AUTOSAR XML (schema 00049)
package /SwComponent/AdaptiveApplication
  adaptive application sw component type Had
    require port VehicleSpeed: required-interface=VehicleSpeed
  adaptive application sw component type Lad
    require port VehicleSpeed: required-interface=VehicleSpeed
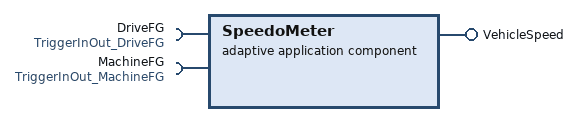
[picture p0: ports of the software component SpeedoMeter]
  adaptive application sw component type SpeedoMeter
    require port DriveFG: required-interface=TriggerInOut_DriveFG
    require port MachineFG: required-interface=TriggerInOut_MachineFG
    provide port VehicleSpeed: provided-interface=VehicleSpeed
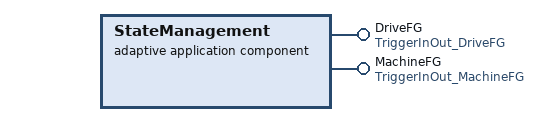
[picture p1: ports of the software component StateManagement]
  adaptive application sw component type StateManagement
    provide port DriveFG: provided-interface=TriggerInOut_DriveFG
    provide port MachineFG: provided-interface=TriggerInOut_MachineFG
package /SwComponent/Composition
  composition sw component type Machine
    4 x component:
      Had: type=Had
      Lad: type=Lad
      SpeedoMeter: type=SpeedoMeter
      StateManagement: type=StateManagement
  composition sw component type System
    component Machine: type=Machine
package /AdaptiveApplication/DltConfig
  6 x dlt log channel to process mapping:
    DltLogChannelToProcessMapping_DltLogChannel_CM_TO_CM: dlt-log-channel=DltLogChannel_CM, process=CM
    DltLogChannelToProcessMapping_DltLogChannel_EM_TO_EM: dlt-log-channel=DltLogChannel_EM, process=EM
    DltLogChannelToProcessMapping_DltLogChannel_Had_TO_Had: dlt-log-channel=DltLogChannel_Had, process=Had
    DltLogChannelToProcessMapping_DltLogChannel_Lad_TO_Lad: dlt-log-channel=DltLogChannel_Lad, process=Lad
    DltLogChannelToProcessMapping_DltLogChannel_Sm_TO_Sm: dlt-log-channel=DltLogChannel_SM, process=SM
    DltLogChannelToProcessMapping_DltLogChannel_SpeedoMeter_TO_SpeedoMeter: dlt-log-channel=DltLogChannel_SpeedoMeter, process=SpeedoMeter
package /AdaptiveApplication/Executable
  6 x executable, all with logging-behavior=USES-LOGGING, version=1.0.0:
    CM: category=PLATFORM_LEVEL, reporting-behavior=REPORTS-EXECUTION-STATE
    EM: category=PLATFORM_LEVEL, reporting-behavior=DOES-NOT-REPORT-EXECUTION-STATE
    Had: category=APPLICATION_LEVEL, reporting-behavior=REPORTS-EXECUTION-STATE
      root sw component prototype Root: application-type=Had
    Lad: category=APPLICATION_LEVEL, reporting-behavior=REPORTS-EXECUTION-STATE
      root sw component prototype Root: application-type=Lad
    SM: category=PLATFORM_LEVEL, reporting-behavior=REPORTS-EXECUTION-STATE
      root sw component prototype Root: application-type=StateManagement
    SpeedoMeter: category=APPLICATION_LEVEL, reporting-behavior=REPORTS-EXECUTION-STATE
      root sw component prototype Root: application-type=SpeedoMeter
package /AdaptiveApplication/Manifest
  7 x service instance to port prototype mapping:
    Had_Root_VehicleSpeed: port-prototype=Root.VehicleSpeed, service-instance=Proxy_VehicleSpeed
    Lad_Root_VehicleSpeed: port-prototype=Root.VehicleSpeed, service-instance=Proxy_VehicleSpeed
    Sm_Root_DriveFG: port-prototype=Root.DriveFG, service-instance=Skeleton_TriggerInOut_DriveFG
    Sm_Root_MachineFG: port-prototype=Root.MachineFG, service-instance=Skeleton_TriggerInOut_MachineFG
    SpeedoMeter_Root_DriveFG: port-prototype=Root.DriveFG, service-instance=Proxy_TriggerInOut_DriveFG
    SpeedoMeter_Root_MachineFG: port-prototype=Root.MachineFG, service-instance=Proxy_TriggerInOut_MachineFG
    SpeedoMeter_Root_VehicleSpeed: port-prototype=Root.VehicleSpeed, service-instance=Skeleton_VehicleSpeed
package /AdaptiveApplication/Process
  6 x process:
    CM: executable=CM, state-dependent-startup-config{function-group-state=[MachineFG.Startup, MachineFG.Restart, MachineFG.Shutdown, MachineFG.Verify], resource-group=NonResourceGroup, startup-config=CM}
      process state machine CM: type=ProcessState
    EM: executable=EM
    Had: executable=Had, state-dependent-startup-config{function-group-state=DriveFG.HighSpd, resource-group=NonResourceGroup, startup-config=Had}
      process state machine Had: type=ProcessState
    Lad: executable=Lad, number-of-restart-attempts=2, state-dependent-startup-config{function-group-state=DriveFG.LowSpd, resource-group=NonResourceGroup, startup-config=Lad}
      process state machine Lad: type=ProcessState
    SM: executable=SM, function-cluster-affiliation=STATE_MANAGEMENT, state-dependent-startup-config{function-group-state=[MachineFG.Startup, MachineFG.Restart, MachineFG.Shutdown, MachineFG.Verify], resource-group=NonResourceGroup, startup-config=SM}
      process state machine SM: type=ProcessState
    SpeedoMeter: executable=SpeedoMeter, state-dependent-startup-config{execution-dependency=SM.Running, function-group-state=MachineFG.Startup, resource-group=NonResourceGroup, startup-config=SpeedoMeter}
      process state machine SpeedoMeter: type=ProcessState
package /AdaptiveApplication/StartupConfig
  startup config set PlatformStartupConfig
    startup config CM: scheduling-policy=SCHED_OTHER, scheduling-priority=0, timeout={enter-timeout-value=1.0, exit-timeout-value=1.0}
  startup config set StartupConfigSet
    4 x startup config, all with scheduling-policy=SCHED_OTHER, scheduling-priority=0, timeout={enter-timeout-value=1.0, exit-timeout-value=1.0}:
      Had
      Lad
      SM
      SpeedoMeter
package /DataType/Implementation/CPP
  14 x std cpp implementation data type:
    DriveState: compu {0x00=kOff, 0x01=kLowSpd, 0x02=kHighSpd, 0x03=kVerify}, type-reference=uint8_t
      namespaces:
        symbol props ara
        symbol props sm
    MachineState: compu {0x00=kOff, 0x01=kStartup, 0x02=kShutdown, 0x03=kRestart, 0x04=kVerify}, type-reference=uint8_t
      namespaces:
        symbol props ara
        symbol props sm
    Speed: type-reference=double
      namespaces:
        symbol props veh
        symbol props sensor
    bool: category=VALUE, type-emitter=FundamentalType
    double: category=VALUE, type-emitter=FundamentalType
    float: category=VALUE, type-emitter=FundamentalType
    int16_t: category=VALUE, header-file=cstdint
    int32_t: category=VALUE, header-file=cstdint
    int64_t: category=VALUE, header-file=cstdint
    int8_t: category=VALUE, header-file=cstdint
    uint16_t: category=VALUE, header-file=cstdint
    uint32_t: category=VALUE, header-file=cstdint
    uint64_t: category=VALUE, header-file=cstdint
    uint8_t: category=VALUE, header-file=cstdint
package /PortInterface/Service
  service interface TriggerInOut_DriveFG
    namespaces:
      symbol props ara
      symbol props sm
      symbol props drivefg
    field Notifier: type=DriveState, has-getter=true, has-notifier=true, has-setter=false
    field Trigger: type=DriveState, has-getter=false, has-notifier=false, has-setter=true
  service interface TriggerInOut_MachineFG
    namespaces:
      symbol props ara
      symbol props sm
      symbol props machinefg
    field Notifier: type=MachineState, has-getter=true, has-notifier=true, has-setter=false
    field Trigger: type=MachineState, has-getter=false, has-notifier=false, has-setter=true
  service interface VehicleSpeed
    namespaces:
      symbol props veh
      symbol props sensor
    events:
      data Speed: type=Speed
package /Platform
  machine Machine: machine-design=Machine, trusted-platform-executable-launch-behavior=NO-TRUSTED-PLATFORM-SUPPORT
    module-instantiations:
      generic module instantiation CmInstantiation: category=COMMUNICATION_MANAGEMENT
      os module instantiation Linux
        resource group NonResourceGroup
        resource group ResourceGroup: cpu-usage=90, mem-usage=1000000000
      log and trace instantiation Log: dlt-ecu-id=Machine
        6 x dlt log channel, all with log-trace-log-modes=CONSOLE:
          DltLogChannel_CM: application-id=CM, context-id=CtxCM, log-trace-default-log-level=FATAL
          DltLogChannel_EM: application-id=EM, context-id=CtxEM, log-trace-default-log-level=FATAL
          DltLogChannel_Had: application-id=Had, context-id=CtxHad, log-trace-default-log-level=INFO
          DltLogChannel_Lad: application-id=Lad, context-id=CtxLad, log-trace-default-log-level=INFO
          DltLogChannel_SM: application-id=SM, context-id=CtxSM, log-trace-default-log-level=INFO
          DltLogChannel_SpeedoMeter: application-id=SpeedoMeter, context-id=CtxSpeedoMeter, log-trace-default-log-level=INFO
    processor CPU
      processor core CORE: core-id=0
package /Platform/FunctionGroup
  function group set FunctionGroupSet
    function-groups:
      mode declaration group prototype DriveFG: type=DriveState
      mode declaration group prototype MachineFG: type=MachineState
package /Platform/ProcessToMachine
  process to machine mapping set ProcessToMachineMappingSet
    6 x process to machine mapping, all with machine=Machine:
      ProcessToMachineMapping_CM_TO_Machine_TO_UnknownModule: process=CM
      ProcessToMachineMapping_EM_TO_Machine_TO_UnknownModule: process=EM
      ProcessToMachineMapping_Had_TO_Machine_TO_UnknownModule: process=Had
      ProcessToMachineMapping_Lad_TO_Machine_TO_UnknownModule: process=Lad
      ProcessToMachineMapping_SM_TO_Machine_TO_UnknownModule: process=SM
      ProcessToMachineMapping_SpeedoMeter_TO_Machine_TO_UnknownModule: process=SpeedoMeter
package /System
  system System: category=MACHINE_DESIGN_EXTRACT, system-version=1.0.0;R2011-PARA
    root-software-compositions:
      root sw composition prototype System: software-composition=System
package /System/Service/Deployment
  someip service interface deployment TriggerInOut_DriveFG: service-interface=TriggerInOut_DriveFG, service-interface-id=11, service-interface-version={major-version=1, minor-version=0}
    someip field deployment Notifier: field=TriggerInOut_DriveFG/Notifier
      get Get_Notifier: method-id=1, transport-protocol=UDP
      notifier Notification_Notifier: event-id=1, transport-protocol=UDP
    someip field deployment Trigger: field=TriggerInOut_DriveFG/Trigger
      set Set_Trigger: method-id=2, transport-protocol=UDP
    someip event group Eventgroup_Notification_Notifier: event-group-id=1, event=Notifier/Notification_Notifier
  someip service interface deployment TriggerInOut_MachineFG: service-interface=TriggerInOut_MachineFG, service-interface-id=12, service-interface-version={major-version=1, minor-version=0}
    someip field deployment Notifier: field=TriggerInOut_MachineFG/Notifier
      get Get_Notifier: method-id=1, transport-protocol=UDP
      notifier Notification_Notifier: event-id=1, transport-protocol=UDP
    someip field deployment Trigger: field=TriggerInOut_MachineFG/Trigger
      set Set_Trigger: method-id=2, transport-protocol=UDP
    someip event group Eventgroup_Notification_Notifier: event-group-id=1, event=Notifier/Notification_Notifier
  someip service interface deployment VehicleSpeed: service-interface=VehicleSpeed, service-interface-id=101, service-interface-version={major-version=1, minor-version=0}
    someip event deployment Speed: event=Speed, event-id=11, transport-protocol=UDP
    someip event group Eventgroup_Speed: event-group-id=1, event=Speed
package /System/Service/Endpoint
  someip service instance to machine mapping ProxyMachineMapping: communication-connector=lo, service-instance=[Proxy_TriggerInOut_DriveFG, Proxy_TriggerInOut_MachineFG, Proxy_VehicleSpeed], tcp-port=10200, udp-port=10200
  someip service instance to machine mapping SkeletonMachineMapping: communication-connector=lo, service-instance=[Skeleton_TriggerInOut_DriveFG, Skeleton_TriggerInOut_MachineFG, Skeleton_VehicleSpeed], tcp-port=10010, udp-port=10010
package /System/Service/Instance
  required someip service instance Proxy_TriggerInOut_DriveFG: service-interface-deployment=TriggerInOut_DriveFG, method-request-propss=[Notifier/Get_Notifier, Trigger/Set_Trigger], required-minor-version=ANY, required-service-instance-id=ANY, sd-client-config=SmClientConfig, version-driven-find-behavior=EXACT-OR-ANY-MINOR-VERSION
    someip required event group Eventgroup_Notification_Notifier: event-group=TriggerInOut_DriveFG/Eventgroup_Notification_Notifier, sd-client-event-group-timing-config=SmSdEventgroupConfig
  required someip service instance Proxy_TriggerInOut_MachineFG: service-interface-deployment=TriggerInOut_MachineFG, method-request-propss=[Notifier/Get_Notifier, Trigger/Set_Trigger], required-minor-version=ANY, required-service-instance-id=ANY, sd-client-config=SmClientConfig, version-driven-find-behavior=EXACT-OR-ANY-MINOR-VERSION
    someip required event group Eventgroup_Notification_Notifier: event-group=TriggerInOut_MachineFG/Eventgroup_Notification_Notifier, sd-client-event-group-timing-config=SmSdEventgroupConfig
  required someip service instance Proxy_VehicleSpeed: service-interface-deployment=VehicleSpeed, required-minor-version=ANY, required-service-instance-id=ANY, sd-client-config=SensorClientConfig, version-driven-find-behavior=EXACT-OR-ANY-MINOR-VERSION
    someip required event group Eventgroup_Speed: event-group=Eventgroup_Speed, sd-client-event-group-timing-config=SensorSdEventgroupConfig
  provided someip service instance Skeleton_TriggerInOut_DriveFG: service-interface-deployment=TriggerInOut_DriveFG, someip-event-props=Notifier/Notification_Notifier, method-response-propss=[Notifier/Get_Notifier, Trigger/Set_Trigger], sd-server-config=SmServerConfig, service-instance-id=1
    someip provided event group Eventgroup_Notification_Notifier: event-group=TriggerInOut_DriveFG/Eventgroup_Notification_Notifier, multicast-threshold=0
  provided someip service instance Skeleton_TriggerInOut_MachineFG: service-interface-deployment=TriggerInOut_MachineFG, someip-event-props=Notifier/Notification_Notifier, method-response-propss=[Notifier/Get_Notifier, Trigger/Set_Trigger], sd-server-config=SmServerConfig, service-instance-id=1
    someip provided event group Eventgroup_Notification_Notifier: event-group=TriggerInOut_MachineFG/Eventgroup_Notification_Notifier, multicast-threshold=0
  provided someip service instance Skeleton_VehicleSpeed: service-interface-deployment=VehicleSpeed, someip-event-props=Speed, sd-server-config=SensorServerConfig, service-instance-id=1
    someip provided event group Eventgroup_Speed: event-group=Eventgroup_Speed, multicast-threshold=0
package /System/Service/TimingConfig
  someip sd client service instance config SensorClientConfig: initial-find-behavior={initial-delay-max-value=0.1, initial-delay-min-value=0.1, initial-repetitions-base-delay=0.1, initial-repetitions-max=3}, service-find-time-to-live=16777215
  someip sd client event group timing config SensorSdEventgroupConfig: request-response-delay={max-value=0.0, min-value=0.0}, time-to-live=16777215
  someip sd server service instance config SensorServerConfig: initial-offer-behavior={initial-delay-max-value=0.1, initial-delay-min-value=0.1, initial-repetitions-base-delay=0.1, initial-repetitions-max=3}, offer-cyclic-delay=0.5, request-response-delay={max-value=0.0, min-value=0.0}, service-offer-time-to-live=16777215
  someip sd client service instance config SmClientConfig: initial-find-behavior={initial-delay-max-value=0.1, initial-delay-min-value=0.1, initial-repetitions-base-delay=0.1, initial-repetitions-max=4}, service-find-time-to-live=16777215
  someip sd client event group timing config SmSdEventgroupConfig: request-response-delay={max-value=0.0, min-value=0.0}, time-to-live=16777215
  someip sd server service instance config SmServerConfig: initial-offer-behavior={initial-delay-max-value=0.1, initial-delay-min-value=0.1, initial-repetitions-base-delay=0.1, initial-repetitions-max=3}, offer-cyclic-delay=0.5, request-response-delay={max-value=0.0, min-value=0.0}, service-offer-time-to-live=16777215
package /System/VehicleTopology/Cluster
  ethernet cluster EthernetCluster
    ethernet physical channel PhysicalChannel: category=WIRED, comm-connectors=eth0
      network endpoint Localhost: network-endpoint-addresses=ipv-4-configuration={ipv-4-address=127.0.0.1, ipv-4-address-source=FIXED}
      network endpoint RemoteEndpoint: network-endpoint-addresses=ipv-4-configuration={ipv-4-address=192.168.0.5, ipv-4-address-source=FIXED}
      network endpoint SdMulticast: network-endpoint-addresses=ipv-4-configuration={ipv-4-address=224.0.0.1, ipv-4-address-source=FIXED}
package /System/VehicleTopology/Ecu
  machine design Machine: service-discover-configs=someip-service-discovery={multicast-sd-ip-address=SdMulticast, someip-service-discovery-port=30490}
    user defined communication connector IPC
    ethernet communication connector eth0: unicast-network-endpoint=RemoteEndpoint
    ethernet communication connector lo: unicast-network-endpoint=Localhost
package /StateMachine
  mode declaration group DriveState: initial-mode=DriveState/Off
    4 x mode:
      HighSpd
      LowSpd
      Off
      Verify
  mode declaration group MachineState: initial-mode=MachineState/Off
    5 x mode:
      Off
      Restart
      Shutdown
      Startup
      Verify
  mode declaration group ProcessState: initial-mode=Idle
    4 x mode:
      Idle
      Running
      Starting
      Terminated
